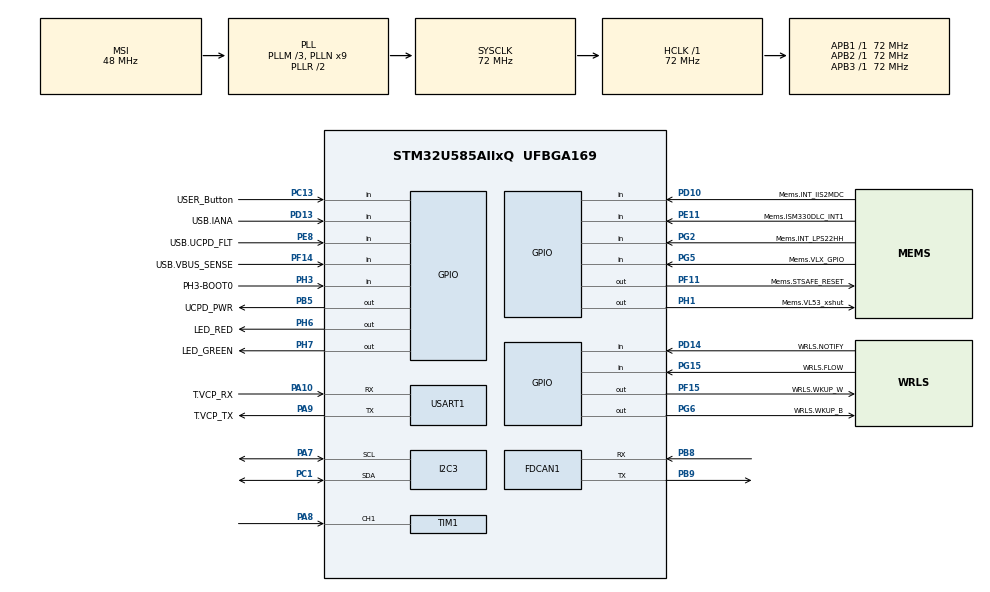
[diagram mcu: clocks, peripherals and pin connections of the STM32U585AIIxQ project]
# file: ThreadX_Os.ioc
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CORTEX_M33_NS.userName=CORTEX_M33
FDCAN1.AutoRetransmission=ENABLE
FDCAN1.CalculateBaudRateNominal=500000
FDCAN1.CalculateTimeBitNominal=2000
FDCAN1.CalculateTimeQuantumNominal=111.11111111111111
FDCAN1.NominalPrescaler=4
FDCAN1.NominalTimeSeg1=15
FDCAN1.NominalTimeSeg2=2
FDCAN1.TxFifoQueueMode=FDCAN_TX_QUEUE_OPERATION
I2C3.Timing=0x10808DD3
Mcu.Family=STM32U5
Mcu.Name=STM32U585AIIxQ
Mcu.Package=UFBGA169
NVIC.PriorityGroup=NVIC_PRIORITYGROUP_4
NVIC.TIM6_IRQn=true\:15\:0\:false\:false\:true\:false\:false\:true\:true
NVIC.TimeBase=TIM6_IRQn
NVIC.TimeBaseIP=TIM6
PA10.GPIO_Label=T.VCP_RX
PA10.Mode=Asynchronous
PA10.Signal=USART1_RX
PA11.GPIO_Label=USB.C_P
PA11.Signal=USB_OTG_FS_DM
PA12.GPIO_Label=USB.C_P
PA12.Signal=USB_OTG_FS_DP
PA13\ (JTMS/SWDIO).GPIO_Label=T.SWDIO
PA13\ (JTMS/SWDIO).Signal=DEBUG_JTMS-SWDIO
PA14\ (JTCK/SWCLK).GPIO_Label=T.SWCLK
PA14\ (JTCK/SWCLK).Signal=DEBUG_JTCK-SWCLK
PA15\ (JTDI).GPIO_Label=USB.UCPD_CC1
PA15\ (JTDI).Signal=UCPD1_CC1
PA7.GPIO_Pu=GPIO_PULLUP
PA7.Mode=I2C
PA7.Signal=I2C3_SCL
PA8.Signal=S_TIM1_CH1
PA9.GPIO_Label=T.VCP_TX
PA9.Mode=Asynchronous
PA9.Signal=USART1_TX
PB1.GPIO_Label=MIC.SDIN0
PB1.Signal=MDF1_SDI0
PB10.GPIO_Label=OCTOSPI.R_CLK_P
PB10.Signal=OCTOSPIM_P1_CLK
PB11.GPIO_Label=OCTOSPI.R_NCS
PB11.Signal=OCTOSPIM_P1_NCS
PB12.GPIO_Label=WRLS.SPI2_NSS
PB12.Signal=SPI2_NSS
PB15.GPIO_Label=USB.UCPD_CC2
PB15.Signal=UCPD1_CC2
PB3\ (JTDO/TRACESWO).GPIO_Label=T.SWO
PB3\ (JTDO/TRACESWO).Signal=DEBUG_JTDO-SWO
PB5.GPIO_Label=UCPD_PWR
PB5.Signal=GPIO_Output
PB8.Mode=FDCAN_Activate
PB8.Signal=FDCAN1_RX
PB9.Mode=FDCAN_Activate
PB9.Signal=FDCAN1_TX
PC1.GPIO_Pu=GPIO_PULLUP
PC1.Mode=I2C
PC1.Signal=I2C3_SDA
PC10.GPIO_Label=WRLS.UART4_TX
PC10.Signal=UART4_TX
PC11.GPIO_Label=WRLS.UART4_RX
PC11.Signal=UART4_RX
PC13.GPIO_Label=USER_Button
PC13.Signal=GPIO_Input
PC14-OSC32_IN\ (PC14).GPIO_Label=PC14-OSC32_IN
PC14-OSC32_IN\ (PC14).Mode=LSE-External-Oscillator
PC14-OSC32_IN\ (PC14).Signal=RCC_OSC32_IN
PC15-OSC32_OUT\ (PC15).GPIO_Label=PC15-OSC32_OUT
PC15-OSC32_OUT\ (PC15).Mode=LSE-External-Oscillator
PC15-OSC32_OUT\ (PC15).Signal=RCC_OSC32_OUT
PC3.GPIO_Label=OCTOSPI.R_IO6
PC3.Signal=OCTOSPIM_P1_IO6
PD1.GPIO_Label=WRLS.SPI2_SCK
PD1.Signal=SPI2_SCK
PD10.GPIO_Label=Mems.INT_IIS2MDC
PD10.Signal=GPIO_Input
PD13.GPIO_Label=USB.IANA
PD13.Signal=GPIO_Input
PD14.GPIO_Label=WRLS.NOTIFY
PD14.Signal=GPIO_Input
PD3.GPIO_Label=WRLS.SPI2_MISO
PD3.Signal=SPI2_MISO
PD4.GPIO_Label=WRLS.SPI2_MOSI
PD4.Signal=SPI2_MOSI
PE10.GPIO_Label=MIC.SDINx
PE10.Signal=ADF1_SDI0
PE11.GPIO_Label=Mems.ISM330DLC_INT1
PE11.Signal=GPIO_Input
PE3.GPIO_Label=OCTOSPI.R_DQS
PE3.Signal=OCTOSPIM_P1_DQS
PE8.GPIO_Label=USB.UCPD_FLT
PE8.Signal=GPIO_Input
PE9.GPIO_Label=MIC.CCK0
PE9.Signal=ADF1_CCK0
PF0.GPIO_Label=OCTOSPI.F_IO0
PF0.Signal=OCTOSPIM_P2_IO0
PF1.GPIO_Label=OCTOSPI.F_IO1
PF1.Signal=OCTOSPIM_P2_IO1
PF10.GPIO_Label=MIC.CCK1
PF10.Signal=MDF1_CCK1
PF11.GPIO_Label=Mems.STSAFE_RESET
PF11.Signal=GPIO_Output
PF12.GPIO_Label=OCTOSPI.F_DQS
PF12.Signal=OCTOSPIM_P2_DQS
PF14.GPIO_Label=USB.VBUS_SENSE
PF14.Signal=GPIO_Input
PF15.GPIO_Label=WRLS.WKUP_W
PF15.Signal=GPIO_Output
PF2.GPIO_Label=OCTOSPI.F_IO2
PF2.Signal=OCTOSPIM_P2_IO2
PF3.GPIO_Label=OCTOSPI.F_IO3
PF3.Signal=OCTOSPIM_P2_IO3
PF4.GPIO_Label=OCTOSPI.F_CLK_P
PF4.Signal=OCTOSPIM_P2_CLK
PF6.GPIO_Label=OCTOSPI.R_IO3
PF6.Signal=OCTOSPIM_P1_IO3
PF7.GPIO_Label=OCTOSPI.R_IO2
PF7.Signal=OCTOSPIM_P1_IO2
PF8.GPIO_Label=OCTOSPI.R_IO0
PF8.Signal=OCTOSPIM_P1_IO0
PF9.GPIO_Label=OCTOSPI.R_IO1
PF9.Signal=OCTOSPIM_P1_IO1
PG15.GPIO_Label=WRLS.FLOW
PG15.Signal=GPIO_Input
PG2.GPIO_Label=Mems.INT_LPS22HH
PG2.Signal=GPIO_Input
PG5.GPIO_Label=Mems.VLX_GPIO
PG5.Signal=GPIO_Input
PG6.GPIO_Label=WRLS.WKUP_B
PG6.Signal=GPIO_Output
PH1-OSC_OUT\ (PH1).GPIO_Label=Mems.VL53_xshut
PH1-OSC_OUT\ (PH1).Signal=GPIO_Output
PH10.GPIO_Label=OCTOSPI.F_IO5
PH10.Signal=OCTOSPIM_P2_IO5
PH11.GPIO_Label=OCTOSPI.F_IO6
PH11.Signal=OCTOSPIM_P2_IO6
PH12.GPIO_Label=OCTOSPI.F_IO7
PH12.Signal=OCTOSPIM_P2_IO7
PH2.GPIO_Label=OCTOSPI.R_IO4
PH2.Signal=OCTOSPIM_P1_IO4
PH3-BOOT0.GPIO_Label=PH3-BOOT0
PH3-BOOT0.Signal=GPIO_Input
PH6.GPIO_Label=LED_RED
PH6.Signal=GPIO_Output
PH7.GPIO_Label=LED_GREEN
PH7.Signal=GPIO_Output
PH9.GPIO_Label=OCTOSPI.F_IO4
PH9.Signal=OCTOSPIM_P2_IO4
PI0.GPIO_Label=OCTOSPI.R_IO5
PI0.Signal=OCTOSPIM_P1_IO5
PI5.GPIO_Label=OCTOSPI.F_NCS
PI5.Signal=OCTOSPIM_P2_NCS
PWR.PowerMode=PWR_SMPS_SUPPLY
ProjectManager.HeapSize=0x200
ProjectManager.StackSize=0x400
ProjectManager.TargetToolchain=CMake
RCC.ADCFreq_Value=16000000
RCC.AHBFreq_Value=72000000
RCC.APB1Freq_Value=72000000
RCC.APB1TimFreq_Value=72000000
RCC.APB2Freq_Value=72000000
RCC.APB2TimFreq_Value=72000000
RCC.APB3Freq_Value=72000000
RCC.CortexFreq_Value=72000000
RCC.DACCLockSelectionVirtual=RCC_DAC1CLKSOURCE_LSI
RCC.EPOD_VALUE=48000000
RCC.HCLKFreq_Value=72000000
RCC.HSE_VALUE=16000000
RCC.HSI48_VALUE=48000000
RCC.HSI_VALUE=16000000
RCC.LSIDIV_VALUE=32000
RCC.MSIClockRange=RCC_MSIRANGE_0
RCC.MSI_VALUE=48000000
RCC.PLL1Q=4
RCC.PLLFRACN=0
RCC.PLLM=3
RCC.PLLN=9
RCC.SYSCLKFreq_VALUE=72000000
RCC.SYSCLKSource=RCC_SYSCLKSOURCE_PLLCLK
RCC.USBFreq_Value=48000000
RCC.VCOOutputFreq_Value=144000000
SH.S_TIM1_CH1.0=TIM1_CH1,TriggerSource_TI1FP1
USART1.VirtualMode-Asynchronous=VM_ASYNC
VP_ICACHE_VS_ICACHE.Mode=DirectMappedCache
VP_LPBAMQUEUE_VS_QUEUE.Mode=QUEUEMODE
VP_LPBAM_VS_SIG1.Mode=SmartRun
VP_LPBAM_VS_SIG4.Mode=LPDMA1
VP_MEMORYMAP_VS_MEMORYMAP.Mode=CurAppReg
VP_PWR_VS_DBSignals.Mode=DisableDeadBatterySignals
VP_PWR_VS_LPOM.Mode=PowerOptimisation
VP_PWR_VS_SECSignals.Mode=Security/Privilege
VP_SYS_VS_tim6.Mode=TIM6
VP_THREADX_VS_RTOSJjThreadXJjCoreJjDefault.Mode=Core_Default
VP_TIM1_VS_ControllerModeClock.Mode=Clock Mode
board=B-U585I-IOT02A

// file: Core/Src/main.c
/* USER CODE BEGIN Header */
/**
  ******************************************************************************
  * @file           : main.c
  * @brief          : Main program body
  ******************************************************************************
  * @attention
  *
  * Copyright (c) 2025 STMicroelectronics.
  * All rights reserved.
  *
  * This software is licensed under terms that can be found in the LICENSE file
  * in the root directory of this software component.
  * If no LICENSE file comes with this software, it is provided AS-IS.
  *
  ******************************************************************************
  */
/* USER CODE END Header */
#include "app_threadx.h"
#include "main.h"

FDCAN_HandleTypeDef hfdcan1;

I2C_HandleTypeDef hi2c3;

TIM_HandleTypeDef htim1;

UART_HandleTypeDef huart1;

void SystemClock_Config(void);
static void SystemPower_Config(void);
static void MX_GPIO_Init(void);
static void MX_ICACHE_Init(void);
static void MX_USART1_UART_Init(void);
static void MX_TIM1_Init(void);
static void MX_FDCAN1_Init(void);
static void MX_I2C3_Init(void);

int main(void)
{

  /* MCU Configuration--------------------------------------------------------*/

  /* Reset of all peripherals, Initializes the Flash interface and the Systick. */
  HAL_Init();

  /* Configure the System Power */
  SystemPower_Config();

  /* Configure the system clock */
  SystemClock_Config();

  /* Initialize all configured peripherals */
  MX_GPIO_Init();
  MX_ICACHE_Init();
  MX_USART1_UART_Init();
  MX_TIM1_Init();
  MX_FDCAN1_Init();
  MX_I2C3_Init();

  MX_ThreadX_Init();

  /* We should never get here as control is now taken by the scheduler */

  /* Infinite loop */
  while (1)
  {

  }
}

void SystemClock_Config(void)
{
  RCC_OscInitTypeDef RCC_OscInitStruct = {0};
  RCC_ClkInitTypeDef RCC_ClkInitStruct = {0};

  /** Configure the main internal regulator output voltage
  */
  if (HAL_PWREx_ControlVoltageScaling(PWR_REGULATOR_VOLTAGE_SCALE2) != HAL_OK)
  {
    Error_Handler();
  }

  /** Initializes the CPU, AHB and APB buses clocks
  */
  RCC_OscInitStruct.OscillatorType = RCC_OSCILLATORTYPE_MSI;
  RCC_OscInitStruct.MSIState = RCC_MSI_ON;
  RCC_OscInitStruct.MSICalibrationValue = RCC_MSICALIBRATION_DEFAULT;
  RCC_OscInitStruct.MSIClockRange = RCC_MSIRANGE_0;
  RCC_OscInitStruct.PLL.PLLState = RCC_PLL_ON;
  RCC_OscInitStruct.PLL.PLLSource = RCC_PLLSOURCE_MSI;
  RCC_OscInitStruct.PLL.PLLMBOOST = RCC_PLLMBOOST_DIV4;
  RCC_OscInitStruct.PLL.PLLM = 3;
  RCC_OscInitStruct.PLL.PLLN = 9;
  RCC_OscInitStruct.PLL.PLLP = 2;
  RCC_OscInitStruct.PLL.PLLQ = 4;
  RCC_OscInitStruct.PLL.PLLR = 2;
  RCC_OscInitStruct.PLL.PLLRGE = RCC_PLLVCIRANGE_1;
  RCC_OscInitStruct.PLL.PLLFRACN = 0;
  if (HAL_RCC_OscConfig(&RCC_OscInitStruct) != HAL_OK)
  {
    Error_Handler();
  }

  /** Initializes the CPU, AHB and APB buses clocks
  */
  RCC_ClkInitStruct.ClockType = RCC_CLOCKTYPE_HCLK|RCC_CLOCKTYPE_SYSCLK
                              |RCC_CLOCKTYPE_PCLK1|RCC_CLOCKTYPE_PCLK2
                              |RCC_CLOCKTYPE_PCLK3;
  RCC_ClkInitStruct.SYSCLKSource = RCC_SYSCLKSOURCE_PLLCLK;
  RCC_ClkInitStruct.AHBCLKDivider = RCC_SYSCLK_DIV1;
  RCC_ClkInitStruct.APB1CLKDivider = RCC_HCLK_DIV1;
  RCC_ClkInitStruct.APB2CLKDivider = RCC_HCLK_DIV1;
  RCC_ClkInitStruct.APB3CLKDivider = RCC_HCLK_DIV1;

  if (HAL_RCC_ClockConfig(&RCC_ClkInitStruct, FLASH_LATENCY_2) != HAL_OK)
  {
    Error_Handler();
  }
}

/**
  * @brief Power Configuration
  * @retval None
  */
static void SystemPower_Config(void)
{
  HAL_PWREx_EnableVddIO2();

  /*
   * Disable the internal Pull-Up in Dead Battery pins of UCPD peripheral
   */
  HAL_PWREx_DisableUCPDDeadBattery();

  /*
   * Switch to SMPS regulator instead of LDO
   */
  if (HAL_PWREx_ConfigSupply(PWR_SMPS_SUPPLY) != HAL_OK)
  {
    Error_Handler();
  }
}

static void MX_FDCAN1_Init(void)
{

  hfdcan1.Instance = FDCAN1;
  hfdcan1.Init.ClockDivider = FDCAN_CLOCK_DIV1;
  hfdcan1.Init.FrameFormat = FDCAN_FRAME_CLASSIC;
  hfdcan1.Init.Mode = FDCAN_MODE_NORMAL;
  hfdcan1.Init.AutoRetransmission = ENABLE;
  hfdcan1.Init.TransmitPause = DISABLE;
  hfdcan1.Init.ProtocolException = DISABLE;
  hfdcan1.Init.NominalPrescaler = 4;
  hfdcan1.Init.NominalSyncJumpWidth = 1;
  hfdcan1.Init.NominalTimeSeg1 = 15;
  hfdcan1.Init.NominalTimeSeg2 = 2;
  hfdcan1.Init.DataPrescaler = 1;
  hfdcan1.Init.DataSyncJumpWidth = 1;
  hfdcan1.Init.DataTimeSeg1 = 1;
  hfdcan1.Init.DataTimeSeg2 = 1;
  hfdcan1.Init.StdFiltersNbr = 0;
  hfdcan1.Init.ExtFiltersNbr = 0;
  hfdcan1.Init.TxFifoQueueMode = FDCAN_TX_QUEUE_OPERATION;
  if (HAL_FDCAN_Init(&hfdcan1) != HAL_OK)
  {
    Error_Handler();
  }
  /* USER CODE BEGIN FDCAN1_Init 2 */
  if (HAL_FDCAN_Start(&hfdcan1) != HAL_OK)
  {
    Error_Handler();
  }
  /* USER CODE END FDCAN1_Init 2 */

}

static void MX_I2C3_Init(void)
{

  hi2c3.Instance = I2C3;
  hi2c3.Init.Timing = 0x10808DD3;
  hi2c3.Init.OwnAddress1 = 0;
  hi2c3.Init.AddressingMode = I2C_ADDRESSINGMODE_7BIT;
  hi2c3.Init.DualAddressMode = I2C_DUALADDRESS_DISABLE;
  hi2c3.Init.OwnAddress2 = 0;
  hi2c3.Init.OwnAddress2Masks = I2C_OA2_NOMASK;
  hi2c3.Init.GeneralCallMode = I2C_GENERALCALL_DISABLE;
  hi2c3.Init.NoStretchMode = I2C_NOSTRETCH_DISABLE;
  if (HAL_I2C_Init(&hi2c3) != HAL_OK)
  {
    Error_Handler();
  }

  /** Configure Analogue filter
  */
  if (HAL_I2CEx_ConfigAnalogFilter(&hi2c3, I2C_ANALOGFILTER_ENABLE) != HAL_OK)
  {
    Error_Handler();
  }

  /** Configure Digital filter
  */
  if (HAL_I2CEx_ConfigDigitalFilter(&hi2c3, 0) != HAL_OK)
  {
    Error_Handler();
  }

}

static void MX_ICACHE_Init(void)
{

  /** Enable instruction cache in 1-way (direct mapped cache)
  */
  if (HAL_ICACHE_ConfigAssociativityMode(ICACHE_1WAY) != HAL_OK)
  {
    Error_Handler();
  }
  if (HAL_ICACHE_Enable() != HAL_OK)
  {
    Error_Handler();
  }

}

static void MX_TIM1_Init(void)
{

  TIM_SlaveConfigTypeDef sSlaveConfig = {0};
  TIM_MasterConfigTypeDef sMasterConfig = {0};

  htim1.Instance = TIM1;
  htim1.Init.Prescaler = 0;
  htim1.Init.CounterMode = TIM_COUNTERMODE_UP;
  htim1.Init.Period = 65535;
  htim1.Init.ClockDivision = TIM_CLOCKDIVISION_DIV1;
  htim1.Init.RepetitionCounter = 0;
  htim1.Init.AutoReloadPreload = TIM_AUTORELOAD_PRELOAD_DISABLE;
  if (HAL_TIM_Base_Init(&htim1) != HAL_OK)
  {
    Error_Handler();
  }
  sSlaveConfig.SlaveMode = TIM_SLAVEMODE_EXTERNAL1;
  sSlaveConfig.InputTrigger = TIM_TS_TI1FP1;
  sSlaveConfig.TriggerPolarity = TIM_TRIGGERPOLARITY_RISING;
  sSlaveConfig.TriggerFilter = 15;
  if (HAL_TIM_SlaveConfigSynchro(&htim1, &sSlaveConfig) != HAL_OK)
  {
    Error_Handler();
  }
  sMasterConfig.MasterOutputTrigger = TIM_TRGO_RESET;
  sMasterConfig.MasterOutputTrigger2 = TIM_TRGO2_RESET;
  sMasterConfig.MasterSlaveMode = TIM_MASTERSLAVEMODE_DISABLE;
  if (HAL_TIMEx_MasterConfigSynchronization(&htim1, &sMasterConfig) != HAL_OK)
  {
    Error_Handler();
  }

}

static void MX_USART1_UART_Init(void)
{

  huart1.Instance = USART1;
  huart1.Init.BaudRate = 115200;
  huart1.Init.WordLength = UART_WORDLENGTH_8B;
  huart1.Init.StopBits = UART_STOPBITS_1;
  huart1.Init.Parity = UART_PARITY_NONE;
  huart1.Init.Mode = UART_MODE_TX_RX;
  huart1.Init.HwFlowCtl = UART_HWCONTROL_NONE;
  huart1.Init.OverSampling = UART_OVERSAMPLING_16;
  huart1.Init.OneBitSampling = UART_ONE_BIT_SAMPLE_DISABLE;
  huart1.Init.ClockPrescaler = UART_PRESCALER_DIV1;
  huart1.AdvancedInit.AdvFeatureInit = UART_ADVFEATURE_NO_INIT;
  if (HAL_UART_Init(&huart1) != HAL_OK)
  {
    Error_Handler();
  }
  if (HAL_UARTEx_SetTxFifoThreshold(&huart1, UART_TXFIFO_THRESHOLD_1_8) != HAL_OK)
  {
    Error_Handler();
  }
  if (HAL_UARTEx_SetRxFifoThreshold(&huart1, UART_RXFIFO_THRESHOLD_1_8) != HAL_OK)
  {
    Error_Handler();
  }
  if (HAL_UARTEx_DisableFifoMode(&huart1) != HAL_OK)
  {
    Error_Handler();
  }

}

static void MX_GPIO_Init(void)
{
  GPIO_InitTypeDef GPIO_InitStruct = {0};

  /* GPIO Ports Clock Enable */
  __HAL_RCC_GPIOG_CLK_ENABLE();
  __HAL_RCC_GPIOC_CLK_ENABLE();
  __HAL_RCC_GPIOA_CLK_ENABLE();
  __HAL_RCC_GPIOI_CLK_ENABLE();
  __HAL_RCC_GPIOH_CLK_ENABLE();
  __HAL_RCC_GPIOB_CLK_ENABLE();
  __HAL_RCC_GPIOD_CLK_ENABLE();
  __HAL_RCC_GPIOE_CLK_ENABLE();
  __HAL_RCC_GPIOF_CLK_ENABLE();

  /*Configure GPIO pin Output Level */
  HAL_GPIO_WritePin(UCPD_PWR_GPIO_Port, UCPD_PWR_Pin, GPIO_PIN_RESET);

  /*Configure GPIO pin Output Level */
  HAL_GPIO_WritePin(GPIOH, LED_RED_Pin|LED_GREEN_Pin|Mems_VL53_xshut_Pin, GPIO_PIN_RESET);

  /*Configure GPIO pin Output Level */
  HAL_GPIO_WritePin(WRLS_WKUP_B_GPIO_Port, WRLS_WKUP_B_Pin, GPIO_PIN_RESET);

  /*Configure GPIO pin Output Level */
  HAL_GPIO_WritePin(GPIOF, Mems_STSAFE_RESET_Pin|WRLS_WKUP_W_Pin, GPIO_PIN_RESET);

  /*Configure GPIO pins : WRLS_FLOW_Pin Mems_VLX_GPIO_Pin Mems_INT_LPS22HH_Pin */
  GPIO_InitStruct.Pin = WRLS_FLOW_Pin|Mems_VLX_GPIO_Pin|Mems_INT_LPS22HH_Pin;
  GPIO_InitStruct.Mode = GPIO_MODE_INPUT;
  GPIO_InitStruct.Pull = GPIO_NOPULL;
  HAL_GPIO_Init(GPIOG, &GPIO_InitStruct);

  /*Configure GPIO pins : WRLS_UART4_RX_Pin WRLS_UART4_TX_Pin */
  GPIO_InitStruct.Pin = WRLS_UART4_RX_Pin|WRLS_UART4_TX_Pin;
  GPIO_InitStruct.Mode = GPIO_MODE_AF_PP;
  GPIO_InitStruct.Pull = GPIO_NOPULL;
  GPIO_InitStruct.Speed = GPIO_SPEED_FREQ_LOW;
  GPIO_InitStruct.Alternate = GPIO_AF8_UART4;
  HAL_GPIO_Init(GPIOC, &GPIO_InitStruct);

  /*Configure GPIO pin : USB_UCPD_CC1_Pin */
  GPIO_InitStruct.Pin = USB_UCPD_CC1_Pin;
  GPIO_InitStruct.Mode = GPIO_MODE_ANALOG;
  GPIO_InitStruct.Pull = GPIO_NOPULL;
  HAL_GPIO_Init(USB_UCPD_CC1_GPIO_Port, &GPIO_InitStruct);

  /*Configure GPIO pin : OCTOSPI_F_NCS_Pin */
  GPIO_InitStruct.Pin = OCTOSPI_F_NCS_Pin;
  GPIO_InitStruct.Mode = GPIO_MODE_AF_PP;
  GPIO_InitStruct.Pull = GPIO_NOPULL;
  GPIO_InitStruct.Speed = GPIO_SPEED_FREQ_VERY_HIGH;
  GPIO_InitStruct.Alternate = GPIO_AF5_OCTOSPI2;
  HAL_GPIO_Init(OCTOSPI_F_NCS_GPIO_Port, &GPIO_InitStruct);

  /*Configure GPIO pin : OCTOSPI_R_IO5_Pin */
  GPIO_InitStruct.Pin = OCTOSPI_R_IO5_Pin;
  GPIO_InitStruct.Mode = GPIO_MODE_AF_PP;
  GPIO_InitStruct.Pull = GPIO_NOPULL;
  GPIO_InitStruct.Speed = GPIO_SPEED_FREQ_VERY_HIGH;
  GPIO_InitStruct.Alternate = GPIO_AF3_OCTOSPI1;
  HAL_GPIO_Init(OCTOSPI_R_IO5_GPIO_Port, &GPIO_InitStruct);

  /*Configure GPIO pins : OCTOSPI_F_IO7_Pin OCTOSPI_F_IO5_Pin OCTOSPI_F_IO6_Pin OCTOSPI_F_IO4_Pin */
  GPIO_InitStruct.Pin = OCTOSPI_F_IO7_Pin|OCTOSPI_F_IO5_Pin|OCTOSPI_F_IO6_Pin|OCTOSPI_F_IO4_Pin;
  GPIO_InitStruct.Mode = GPIO_MODE_AF_PP;
  GPIO_InitStruct.Pull = GPIO_NOPULL;
  GPIO_InitStruct.Speed = GPIO_SPEED_FREQ_VERY_HIGH;
  GPIO_InitStruct.Alternate = GPIO_AF5_OCTOSPI2;
  HAL_GPIO_Init(GPIOH, &GPIO_InitStruct);

  /*Configure GPIO pin : PH3_BOOT0_Pin */
  GPIO_InitStruct.Pin = PH3_BOOT0_Pin;
  GPIO_InitStruct.Mode = GPIO_MODE_INPUT;
  GPIO_InitStruct.Pull = GPIO_NOPULL;
  HAL_GPIO_Init(PH3_BOOT0_GPIO_Port, &GPIO_InitStruct);

  /*Configure GPIO pin : UCPD_PWR_Pin */
  GPIO_InitStruct.Pin = UCPD_PWR_Pin;
  GPIO_InitStruct.Mode = GPIO_MODE_OUTPUT_PP;
  GPIO_InitStruct.Pull = GPIO_NOPULL;
  GPIO_InitStruct.Speed = GPIO_SPEED_FREQ_LOW;
  HAL_GPIO_Init(UCPD_PWR_GPIO_Port, &GPIO_InitStruct);

  /*Configure GPIO pins : WRLS_SPI2_MOSI_Pin WRLS_SPI2_MISO_Pin WRLS_SPI2_SCK_Pin */
  GPIO_InitStruct.Pin = WRLS_SPI2_MOSI_Pin|WRLS_SPI2_MISO_Pin|WRLS_SPI2_SCK_Pin;
  GPIO_InitStruct.Mode = GPIO_MODE_AF_PP;
  GPIO_InitStruct.Pull = GPIO_NOPULL;
  GPIO_InitStruct.Speed = GPIO_SPEED_FREQ_LOW;
  GPIO_InitStruct.Alternate = GPIO_AF5_SPI2;
  HAL_GPIO_Init(GPIOD, &GPIO_InitStruct);

  /*Configure GPIO pin : OCTOSPI_R_DQS_Pin */
  GPIO_InitStruct.Pin = OCTOSPI_R_DQS_Pin;
  GPIO_InitStruct.Mode = GPIO_MODE_AF_PP;
  GPIO_InitStruct.Pull = GPIO_NOPULL;
  GPIO_InitStruct.Speed = GPIO_SPEED_FREQ_VERY_HIGH;
  GPIO_InitStruct.Alternate = GPIO_AF3_OCTOSPI1;
  HAL_GPIO_Init(OCTOSPI_R_DQS_GPIO_Port, &GPIO_InitStruct);

  /*Configure GPIO pins : OCTOSPI_F_IO0_Pin OCTOSPI_F_IO1_Pin OCTOSPI_F_IO2_Pin OCTOSPI_F_IO3_Pin
                           OCTOSPI_F_CLK_P_Pin OCTOSPI_F_DQS_Pin */
  GPIO_InitStruct.Pin = OCTOSPI_F_IO0_Pin|OCTOSPI_F_IO1_Pin|OCTOSPI_F_IO2_Pin|OCTOSPI_F_IO3_Pin
                          |OCTOSPI_F_CLK_P_Pin|OCTOSPI_F_DQS_Pin;
  GPIO_InitStruct.Mode = GPIO_MODE_AF_PP;
  GPIO_InitStruct.Pull = GPIO_NOPULL;
  GPIO_InitStruct.Speed = GPIO_SPEED_FREQ_VERY_HIGH;
  GPIO_InitStruct.Alternate = GPIO_AF5_OCTOSPI2;
  HAL_GPIO_Init(GPIOF, &GPIO_InitStruct);

  /*Configure GPIO pin : USER_Button_Pin */
  GPIO_InitStruct.Pin = USER_Button_Pin;
  GPIO_InitStruct.Mode = GPIO_MODE_INPUT;
  GPIO_InitStruct.Pull = GPIO_NOPULL;
  HAL_GPIO_Init(USER_Button_GPIO_Port, &GPIO_InitStruct);

  /*Configure GPIO pins : LED_RED_Pin LED_GREEN_Pin Mems_VL53_xshut_Pin */
  GPIO_InitStruct.Pin = LED_RED_Pin|LED_GREEN_Pin|Mems_VL53_xshut_Pin;
  GPIO_InitStruct.Mode = GPIO_MODE_OUTPUT_PP;
  GPIO_InitStruct.Pull = GPIO_NOPULL;
  GPIO_InitStruct.Speed = GPIO_SPEED_FREQ_LOW;
  HAL_GPIO_Init(GPIOH, &GPIO_InitStruct);

  /*Configure GPIO pins : OCTOSPI_R_IO0_Pin OCTOSPI_R_IO2_Pin OCTOSPI_R_IO1_Pin OCTOSPI_R_IO3_Pin */
  GPIO_InitStruct.Pin = OCTOSPI_R_IO0_Pin|OCTOSPI_R_IO2_Pin|OCTOSPI_R_IO1_Pin|OCTOSPI_R_IO3_Pin;
  GPIO_InitStruct.Mode = GPIO_MODE_AF_PP;
  GPIO_InitStruct.Pull = GPIO_NOPULL;
  GPIO_InitStruct.Speed = GPIO_SPEED_FREQ_VERY_HIGH;
  GPIO_InitStruct.Alternate = GPIO_AF10_OCTOSPI1;
  HAL_GPIO_Init(GPIOF, &GPIO_InitStruct);

  /*Configure GPIO pin : OCTOSPI_R_IO4_Pin */
  GPIO_InitStruct.Pin = OCTOSPI_R_IO4_Pin;
  GPIO_InitStruct.Mode = GPIO_MODE_AF_PP;
  GPIO_InitStruct.Pull = GPIO_NOPULL;
  GPIO_InitStruct.Speed = GPIO_SPEED_FREQ_VERY_HIGH;
  GPIO_InitStruct.Alternate = GPIO_AF3_OCTOSPI1;
  HAL_GPIO_Init(OCTOSPI_R_IO4_GPIO_Port, &GPIO_InitStruct);

  /*Configure GPIO pins : USB_C_P_Pin USB_C_PA11_Pin */
  GPIO_InitStruct.Pin = USB_C_P_Pin|USB_C_PA11_Pin;
  GPIO_InitStruct.Mode = GPIO_MODE_AF_PP;
  GPIO_InitStruct.Pull = GPIO_NOPULL;
  GPIO_InitStruct.Speed = GPIO_SPEED_FREQ_LOW;
  GPIO_InitStruct.Alternate = GPIO_AF10_USB;
  HAL_GPIO_Init(GPIOA, &GPIO_InitStruct);

  /*Configure GPIO pin : MIC_CCK1_Pin */
  GPIO_InitStruct.Pin = MIC_CCK1_Pin;
  GPIO_InitStruct.Mode = GPIO_MODE_AF_PP;
  GPIO_InitStruct.Pull = GPIO_NOPULL;
  GPIO_InitStruct.Speed = GPIO_SPEED_FREQ_LOW;
  GPIO_InitStruct.Alternate = GPIO_AF6_MDF1;
  HAL_GPIO_Init(MIC_CCK1_GPIO_Port, &GPIO_InitStruct);

  /*Configure GPIO pins : MIC_SDINx_Pin MIC_CCK0_Pin */
  GPIO_InitStruct.Pin = MIC_SDINx_Pin|MIC_CCK0_Pin;
  GPIO_InitStruct.Mode = GPIO_MODE_AF_PP;
  GPIO_InitStruct.Pull = GPIO_NOPULL;
  GPIO_InitStruct.Speed = GPIO_SPEED_FREQ_LOW;
  GPIO_InitStruct.Alternate = GPIO_AF3_ADF1;
  HAL_GPIO_Init(GPIOE, &GPIO_InitStruct);

  /*Configure GPIO pin : WRLS_WKUP_B_Pin */
  GPIO_InitStruct.Pin = WRLS_WKUP_B_Pin;
  GPIO_InitStruct.Mode = GPIO_MODE_OUTPUT_PP;
  GPIO_InitStruct.Pull = GPIO_NOPULL;
  GPIO_InitStruct.Speed = GPIO_SPEED_FREQ_LOW;
  HAL_GPIO_Init(WRLS_WKUP_B_GPIO_Port, &GPIO_InitStruct);

  /*Configure GPIO pins : WRLS_NOTIFY_Pin Mems_INT_IIS2MDC_Pin USB_IANA_Pin */
  GPIO_InitStruct.Pin = WRLS_NOTIFY_Pin|Mems_INT_IIS2MDC_Pin|USB_IANA_Pin;
  GPIO_InitStruct.Mode = GPIO_MODE_INPUT;
  GPIO_InitStruct.Pull = GPIO_NOPULL;
  HAL_GPIO_Init(GPIOD, &GPIO_InitStruct);

  /*Configure GPIO pin : OCTOSPI_R_IO6_Pin */
  GPIO_InitStruct.Pin = OCTOSPI_R_IO6_Pin;
  GPIO_InitStruct.Mode = GPIO_MODE_AF_PP;
  GPIO_InitStruct.Pull = GPIO_NOPULL;
  GPIO_InitStruct.Speed = GPIO_SPEED_FREQ_VERY_HIGH;
  GPIO_InitStruct.Alternate = GPIO_AF10_OCTOSPI1;
  HAL_GPIO_Init(OCTOSPI_R_IO6_GPIO_Port, &GPIO_InitStruct);

  /*Configure GPIO pins : USB_UCPD_FLT_Pin Mems_ISM330DLC_INT1_Pin */
  GPIO_InitStruct.Pin = USB_UCPD_FLT_Pin|Mems_ISM330DLC_INT1_Pin;
  GPIO_InitStruct.Mode = GPIO_MODE_INPUT;
  GPIO_InitStruct.Pull = GPIO_NOPULL;
  HAL_GPIO_Init(GPIOE, &GPIO_InitStruct);

  /*Configure GPIO pins : OCTOSPI_R_CLK_P_Pin OCTOSPI_R_NCS_Pin */
  GPIO_InitStruct.Pin = OCTOSPI_R_CLK_P_Pin|OCTOSPI_R_NCS_Pin;
  GPIO_InitStruct.Mode = GPIO_MODE_AF_PP;
  GPIO_InitStruct.Pull = GPIO_NOPULL;
  GPIO_InitStruct.Speed = GPIO_SPEED_FREQ_VERY_HIGH;
  GPIO_InitStruct.Alternate = GPIO_AF10_OCTOSPI1;
  HAL_GPIO_Init(GPIOB, &GPIO_InitStruct);

  /*Configure GPIO pin : USB_VBUS_SENSE_Pin */
  GPIO_InitStruct.Pin = USB_VBUS_SENSE_Pin;
  GPIO_InitStruct.Mode = GPIO_MODE_INPUT;
  GPIO_InitStruct.Pull = GPIO_NOPULL;
  HAL_GPIO_Init(USB_VBUS_SENSE_GPIO_Port, &GPIO_InitStruct);

  /*Configure GPIO pin : WRLS_SPI2_NSS_Pin */
  GPIO_InitStruct.Pin = WRLS_SPI2_NSS_Pin;
  GPIO_InitStruct.Mode = GPIO_MODE_AF_PP;
  GPIO_InitStruct.Pull = GPIO_NOPULL;
  GPIO_InitStruct.Speed = GPIO_SPEED_FREQ_LOW;
  GPIO_InitStruct.Alternate = GPIO_AF5_SPI2;
  HAL_GPIO_Init(WRLS_SPI2_NSS_GPIO_Port, &GPIO_InitStruct);

  /*Configure GPIO pin : USB_UCPD_CC2_Pin */
  GPIO_InitStruct.Pin = USB_UCPD_CC2_Pin;
  GPIO_InitStruct.Mode = GPIO_MODE_ANALOG;
  GPIO_InitStruct.Pull = GPIO_NOPULL;
  HAL_GPIO_Init(USB_UCPD_CC2_GPIO_Port, &GPIO_InitStruct);

  /*Configure GPIO pins : Mems_STSAFE_RESET_Pin WRLS_WKUP_W_Pin */
  GPIO_InitStruct.Pin = Mems_STSAFE_RESET_Pin|WRLS_WKUP_W_Pin;
  GPIO_InitStruct.Mode = GPIO_MODE_OUTPUT_PP;
  GPIO_InitStruct.Pull = GPIO_NOPULL;
  GPIO_InitStruct.Speed = GPIO_SPEED_FREQ_LOW;
  HAL_GPIO_Init(GPIOF, &GPIO_InitStruct);

  /*Configure GPIO pin : MIC_SDIN0_Pin */
  GPIO_InitStruct.Pin = MIC_SDIN0_Pin;
  GPIO_InitStruct.Mode = GPIO_MODE_AF_PP;
  GPIO_InitStruct.Pull = GPIO_NOPULL;
  GPIO_InitStruct.Speed = GPIO_SPEED_FREQ_LOW;
  GPIO_InitStruct.Alternate = GPIO_AF6_MDF1;
  HAL_GPIO_Init(MIC_SDIN0_GPIO_Port, &GPIO_InitStruct);

}

void HAL_TIM_PeriodElapsedCallback(TIM_HandleTypeDef *htim)
{
  if (htim->Instance == TIM6)
  {
    HAL_IncTick();
  }
}

void Error_Handler(void)
{
  __disable_irq();
  while (1)
  {
  }
}
